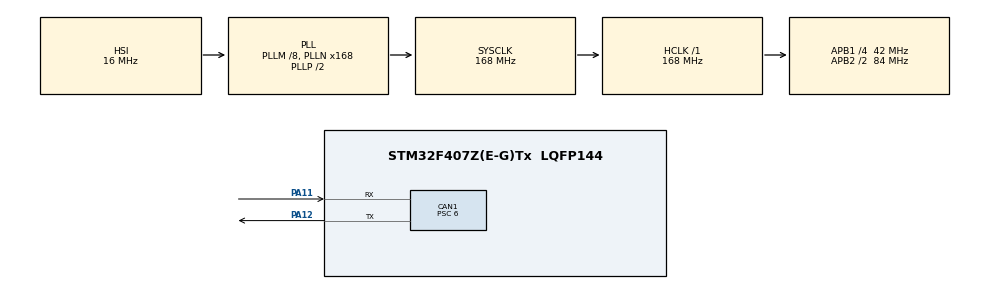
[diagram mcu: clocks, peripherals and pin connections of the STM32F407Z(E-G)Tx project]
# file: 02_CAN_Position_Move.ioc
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CAN1.ABOM=ENABLE
CAN1.BS1=CAN_BS1_10TQ
CAN1.BS2=CAN_BS2_3TQ
CAN1.CalculateBaudRate=500000
CAN1.CalculateTimeBit=2000
CAN1.CalculateTimeQuantum=142.85714285714286
CAN1.NART=DISABLE
CAN1.Prescaler=6
Mcu.Family=STM32F4
Mcu.Name=STM32F407Z(E-G)Tx
Mcu.Package=LQFP144
NVIC.CAN1_RX0_IRQn=true\:0\:0\:false\:false\:true\:true\:true\:true
NVIC.PriorityGroup=NVIC_PRIORITYGROUP_4
PA11.Mode=CAN_Activate
PA11.Signal=CAN1_RX
PA12.Mode=CAN_Activate
PA12.Signal=CAN1_TX
PA13.Mode=Serial_Wire
PA13.Signal=SYS_JTMS-SWDIO
PA14.Mode=Serial_Wire
PA14.Signal=SYS_JTCK-SWCLK
PH0-OSC_IN.Mode=HSE-External-Oscillator
PH0-OSC_IN.Signal=RCC_OSC_IN
PH1-OSC_OUT.Mode=HSE-External-Oscillator
PH1-OSC_OUT.Signal=RCC_OSC_OUT
ProjectManager.HeapSize=0x200
ProjectManager.StackSize=0x400
ProjectManager.TargetToolchain=MDK-ARM V5.32
RCC.48MHZClocksFreq_Value=84000000
RCC.AHBFreq_Value=168000000
RCC.APB1CLKDivider=RCC_HCLK_DIV4
RCC.APB1Freq_Value=42000000
RCC.APB1TimFreq_Value=84000000
RCC.APB2CLKDivider=RCC_HCLK_DIV2
RCC.APB2Freq_Value=84000000
RCC.APB2TimFreq_Value=168000000
RCC.CortexFreq_Value=168000000
RCC.HCLKFreq_Value=168000000
RCC.HSE_VALUE=25000000
RCC.HSI_VALUE=16000000
RCC.LSE_VALUE=32768
RCC.PLLM=8
RCC.PLLN=168
RCC.SYSCLKFreq_VALUE=168000000
RCC.SYSCLKSource=RCC_SYSCLKSOURCE_PLLCLK
RCC.VCOOutputFreq_Value=336000000
board=custom

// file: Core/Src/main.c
/* USER CODE BEGIN Header */
/**
  ******************************************************************************
  * @file           : main.c
  * @brief          : Main program body
  ******************************************************************************
  * @attention
  *
  * Copyright (c) 2026 STMicroelectronics.
  * All rights reserved.
  *
  * This software is licensed under terms that can be found in the LICENSE file
  * in the root directory of this software component.
  * If no LICENSE file comes with this software, it is provided AS-IS.
  *
  ******************************************************************************
  */
/* USER CODE END Header */
#include "main.h"
#include "can.h"
#include "gpio.h"

/* USER CODE BEGIN Includes */
#include "mks_motor.h"
/* USER CODE END Includes */

void SystemClock_Config(void);

int main(void)
{

  /* MCU Configuration--------------------------------------------------------*/

  /* Reset of all peripherals, Initializes the Flash interface and the Systick. */
  HAL_Init();

  /* Configure the system clock */
  SystemClock_Config();

  /* Initialize all configured peripherals */
  MX_GPIO_Init(); // 初始化普通 GPIO
  MX_CAN1_Init();// 初始化 CAN 外设参数、CAN 引脚、时钟等
  /* USER CODE BEGIN 2 */
MKS_Motor_System_Init();      // 初始化你自己的电机结构体，比如 ID
STM32_bxCAN_Filter_Config();     // 配置 CAN 接收过滤器

HAL_CAN_Start(&hcan1);        // 启动 CAN 外设
HAL_CAN_ActivateNotification(&hcan1, CAN_IT_RX_FIFO0_MSG_PENDING); // 打开 FIFO0 接收中断通知

HAL_Delay(100);
MKS_Set_Enable_State(&Motor_X, 1); // 发送使能命令
HAL_Delay(500);

MKS_Move_Relative_Axis(&Motor_X, 60, 2, 8192);
  /* USER CODE END 2 */

  /* Infinite loop */
  while (1)
  {

    /* USER CODE BEGIN 3 */
      // ÿ�� 50 ���룬��Ƭ�����Զ���һ�� 1 �ŵ�����ţ���Ҫ��������
    MKS_Read_Absolute_Position(&Motor_X);

    HAL_Delay(50);
  }
  /* USER CODE END 3 */
}

void SystemClock_Config(void)
{
  RCC_OscInitTypeDef RCC_OscInitStruct = {0};
  RCC_ClkInitTypeDef RCC_ClkInitStruct = {0};

  /** Configure the main internal regulator output voltage
  */
  __HAL_RCC_PWR_CLK_ENABLE();
  __HAL_PWR_VOLTAGESCALING_CONFIG(PWR_REGULATOR_VOLTAGE_SCALE1);

  /** Initializes the RCC Oscillators according to the specified parameters
  * in the RCC_OscInitTypeDef structure.
  */
  RCC_OscInitStruct.OscillatorType = RCC_OSCILLATORTYPE_HSI;
  RCC_OscInitStruct.HSIState = RCC_HSI_ON;
  RCC_OscInitStruct.HSICalibrationValue = RCC_HSICALIBRATION_DEFAULT;
  RCC_OscInitStruct.PLL.PLLState = RCC_PLL_ON;
  RCC_OscInitStruct.PLL.PLLSource = RCC_PLLSOURCE_HSI;
  RCC_OscInitStruct.PLL.PLLM = 8;
  RCC_OscInitStruct.PLL.PLLN = 168;
  RCC_OscInitStruct.PLL.PLLP = RCC_PLLP_DIV2;
  RCC_OscInitStruct.PLL.PLLQ = 4;
  if (HAL_RCC_OscConfig(&RCC_OscInitStruct) != HAL_OK)
  {
    Error_Handler();
  }

  /** Initializes the CPU, AHB and APB buses clocks
  */
  RCC_ClkInitStruct.ClockType = RCC_CLOCKTYPE_HCLK|RCC_CLOCKTYPE_SYSCLK
                              |RCC_CLOCKTYPE_PCLK1|RCC_CLOCKTYPE_PCLK2;
  RCC_ClkInitStruct.SYSCLKSource = RCC_SYSCLKSOURCE_PLLCLK;
  RCC_ClkInitStruct.AHBCLKDivider = RCC_SYSCLK_DIV1;
  RCC_ClkInitStruct.APB1CLKDivider = RCC_HCLK_DIV4;
  RCC_ClkInitStruct.APB2CLKDivider = RCC_HCLK_DIV2;

  if (HAL_RCC_ClockConfig(&RCC_ClkInitStruct, FLASH_LATENCY_5) != HAL_OK)
  {
    Error_Handler();
  }
}

void Error_Handler(void)
{
  __disable_irq();
  while (1)
  {
  }
}
